# LPC43xx register map
File version: 10
CPU: CM4 r0p0, little endian, no MPU, no FPU, 3 interrupt priority bits
Registers are 32-bit, read-write, reset 0x0 unless marked. A register's access mark holds for its fields unless they carry their own. Offsets are from the block's base; [hi:lo] are bit positions; 'fields as' and 'values as' point back to an identical list.

## CCU1 — Clock Control Unit (CCU)
Base 0x40051000
0x00 PM — CCU1 power mode register
  [0] PD — Initiate power-down mode
    0=NORMAL_OPERATION_; 1=CLOCKS_WITH_WAKE_UP_ (Clocks with wake-up mode enabled (W = 1) are disabled.)
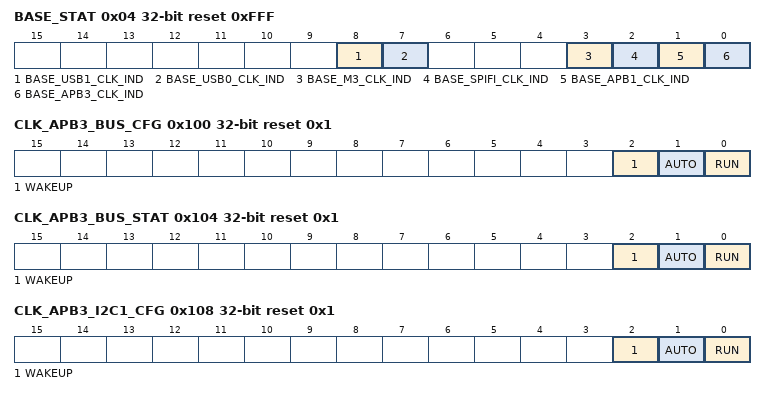
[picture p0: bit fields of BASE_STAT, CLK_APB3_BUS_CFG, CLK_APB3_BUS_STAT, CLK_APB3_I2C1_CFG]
0x04 BASE_STAT ro reset 0xFFF — CCU1 base clocks status register
  [8] BASE_USB1_CLK_IND — Base clock indicator for BASE_USB1_CLK 0 = All branch clocks switched off. 1 = at least one branch clock running.
  [7] BASE_USB0_CLK_IND — Base clock indicator for BASE_USB0_CLK 0 = All branch clocks switched off. 1 = At least one branch clock running.
  [3] BASE_M3_CLK_IND — Base clock indicator for BASE_M3_CLK 0 = All branch clocks switched off. 1 = At least one branch clock running.
  [2] BASE_SPIFI_CLK_IND — Base clock indicator for BASE_SPIFI_CLK 0 = All branch clocks switched off. 1 = At least one branch clock running.
  [1] BASE_APB1_CLK_IND — Base clock indicator for BASE_APB1_CLK 0 = All branch clocks switched off. 1 = At least one branch clock running.
  [0] BASE_APB3_CLK_IND — Base clock indicator for BASE_APB3_CLK 0 = All branch clocks switched off. 1 = At least one branch clock running.
0x100 CLK_APB3_BUS_CFG reset 0x1 — CLK_APB3_BUS clock configuration register
  [2] WAKEUP — Wake-up mechanism enable
    0=DISABLED (Wake-up is disabled.); 1=ENABLED (Wake-up is enabled.)
  [1] AUTO — Auto (AHB disable mechanism) enable
    0=DISABLED_ (Auto is disabled.); 1=ENABLED (Auto is enabled.)
  [0] RUN — Run enable
    0=DISABLED (Clock is disabled.); 1=ENABLED (Clock is enabled.)
0x104 CLK_APB3_BUS_STAT ro reset 0x1 — CLK_APB3_BUS clock status register
  [2] WAKEUP — Wake-up mechanism enable status 0 = Wake-up is disabled. 1 = Wake-up is enabled.
  [1] AUTO — Auto (AHB disable mechanism) enable status 0 = Auto is disabled. 1 = Auto is enabled.
  [0] RUN — Run enable status 0 = clock is disabled. 1 = clock is enabled.
0x108 CLK_APB3_I2C1_CFG reset 0x1 — CLK_APB3_I2C1 clock configuration register
  fields as CLK_APB3_BUS_CFG
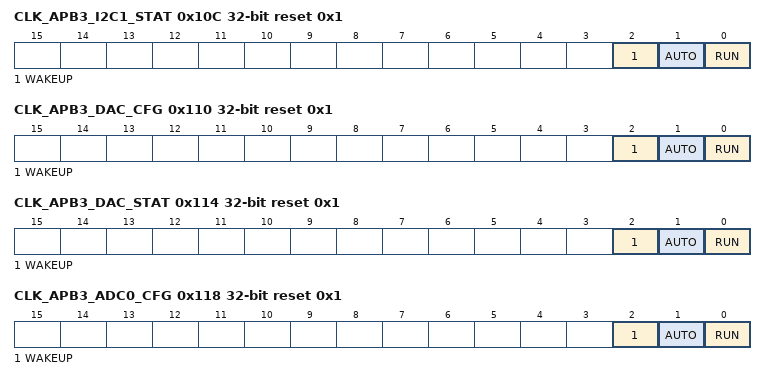
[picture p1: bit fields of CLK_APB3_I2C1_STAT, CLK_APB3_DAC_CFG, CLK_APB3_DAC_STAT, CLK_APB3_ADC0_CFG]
0x10C CLK_APB3_I2C1_STAT ro reset 0x1 — CLK_APB3_I2C1 clock status register
  fields as CLK_APB3_BUS_STAT
0x110 CLK_APB3_DAC_CFG reset 0x1 — CLK_APB3_DAC clock configuration register
  fields as CLK_APB3_BUS_CFG
0x114 CLK_APB3_DAC_STAT ro reset 0x1 — CLK_APB3_DAC clock status register
  fields as CLK_APB3_BUS_STAT
0x118 CLK_APB3_ADC0_CFG reset 0x1 — CLK_APB3_ADC0 clock configuration register
  fields as CLK_APB3_BUS_CFG
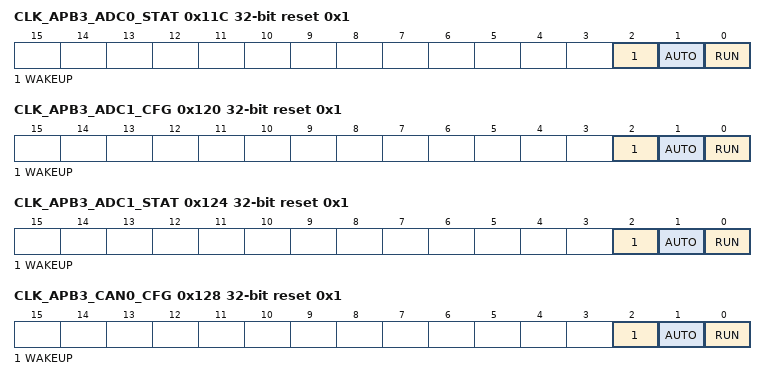
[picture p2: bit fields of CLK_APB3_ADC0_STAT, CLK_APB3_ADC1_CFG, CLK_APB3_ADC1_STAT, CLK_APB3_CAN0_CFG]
0x11C CLK_APB3_ADC0_STAT ro reset 0x1 — CLK_APB3_ADC0 clock status register
  fields as CLK_APB3_BUS_STAT
0x120 CLK_APB3_ADC1_CFG reset 0x1 — CLK_APB3_ADC1 clock configuration register
  fields as CLK_APB3_BUS_CFG
0x124 CLK_APB3_ADC1_STAT ro reset 0x1 — CLK_APB3_ADC1 clock status register
  fields as CLK_APB3_BUS_STAT
0x128 CLK_APB3_CAN0_CFG reset 0x1 — CLK_APB3_CAN0 clock configuration register
  fields as CLK_APB3_BUS_CFG
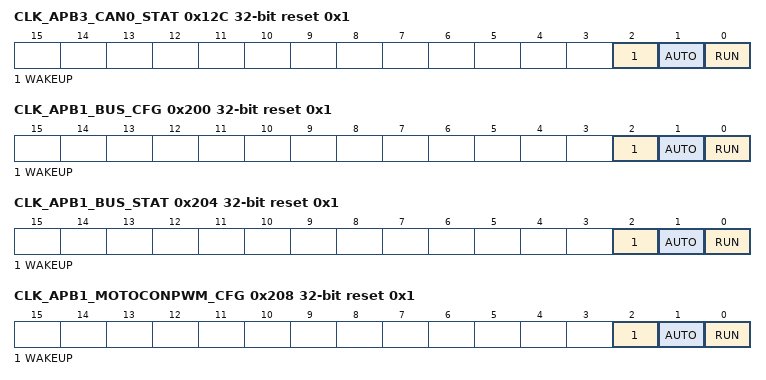
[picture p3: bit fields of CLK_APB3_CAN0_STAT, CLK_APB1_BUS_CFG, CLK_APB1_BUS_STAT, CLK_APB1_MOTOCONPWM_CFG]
0x12C CLK_APB3_CAN0_STAT ro reset 0x1 — CLK_APB3_CAN0 clock status register
  fields as CLK_APB3_BUS_STAT
0x200 CLK_APB1_BUS_CFG reset 0x1 — CLK_APB1_BUS clock configuration register
  fields as CLK_APB3_BUS_CFG
0x204 CLK_APB1_BUS_STAT ro reset 0x1 — CLK_APB1_BUS clock status register
  fields as CLK_APB3_BUS_STAT
0x208 CLK_APB1_MOTOCONPWM_CFG reset 0x1 — CLK_APB1_MOTOCONPWM clock configuration register
  fields as CLK_APB3_BUS_CFG
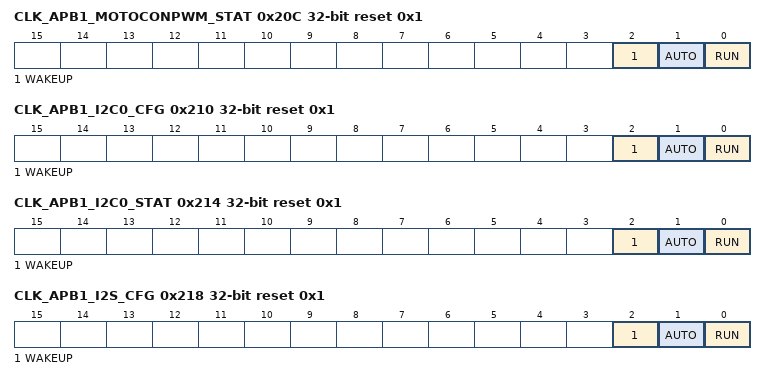
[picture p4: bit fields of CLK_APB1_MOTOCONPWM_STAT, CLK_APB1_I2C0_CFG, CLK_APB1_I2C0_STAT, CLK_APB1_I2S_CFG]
0x20C CLK_APB1_MOTOCONPWM_STAT ro reset 0x1 — CLK_APB1_MOTOCONPWM clock status register
  fields as CLK_APB3_BUS_STAT
0x210 CLK_APB1_I2C0_CFG reset 0x1 — CLK_ABP1_I2C0 clock configuration register
  fields as CLK_APB3_BUS_CFG
0x214 CLK_APB1_I2C0_STAT ro reset 0x1 — CLK_APB1_I2C0 clock status register
  fields as CLK_APB3_BUS_STAT
0x218 CLK_APB1_I2S_CFG reset 0x1 — CLK_APB1_I2S clock configuration register
  fields as CLK_APB3_BUS_CFG
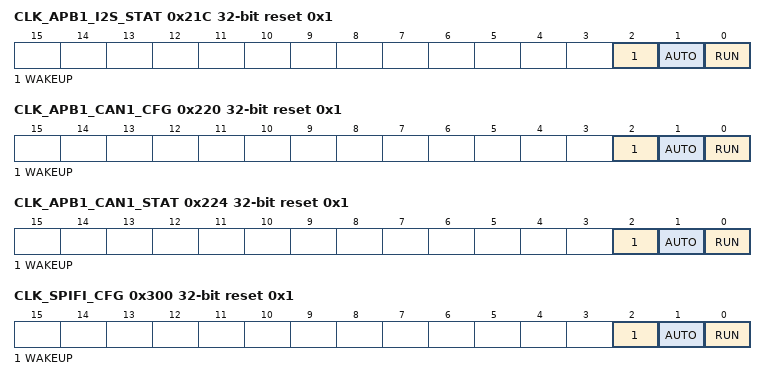
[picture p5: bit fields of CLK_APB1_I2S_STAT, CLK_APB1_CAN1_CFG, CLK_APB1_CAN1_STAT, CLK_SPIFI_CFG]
0x21C CLK_APB1_I2S_STAT ro reset 0x1 — CLK_APB1_I2S clock status register
  fields as CLK_APB3_BUS_STAT
0x220 CLK_APB1_CAN1_CFG reset 0x1 — CLK_APB1_CAN1 clock configuration register
  fields as CLK_APB3_BUS_CFG
0x224 CLK_APB1_CAN1_STAT ro reset 0x1 — CLK_APB1_CAN1 clock status register
  fields as CLK_APB3_BUS_STAT
0x300 CLK_SPIFI_CFG reset 0x1 — CLK_SPIFI clock configuration register
  fields as CLK_APB3_BUS_CFG
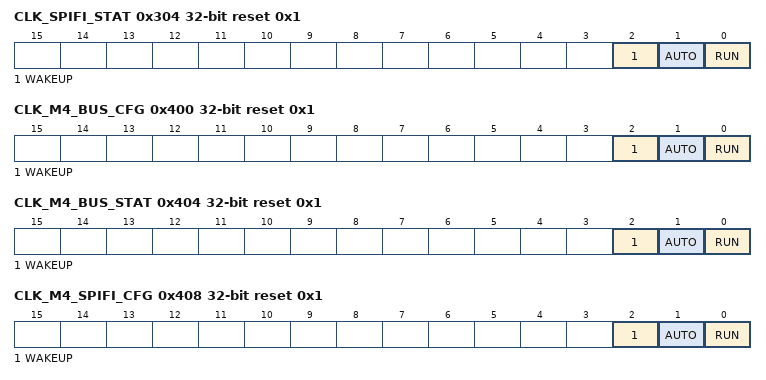
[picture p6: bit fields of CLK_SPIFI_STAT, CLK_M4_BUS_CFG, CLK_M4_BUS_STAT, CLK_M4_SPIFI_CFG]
0x304 CLK_SPIFI_STAT ro reset 0x1 — CLK_APB1_SPIFI clock status register
  fields as CLK_APB3_BUS_STAT
0x400 CLK_M4_BUS_CFG reset 0x1 — CLK_M4_BUS clock configuration register
  fields as CLK_APB3_BUS_CFG
0x404 CLK_M4_BUS_STAT ro reset 0x1 — CLK_M4_BUSclock status register
  fields as CLK_APB3_BUS_STAT
0x408 CLK_M4_SPIFI_CFG reset 0x1 — CLK_M4_SPIFI clock configuration register
  fields as CLK_APB3_BUS_CFG
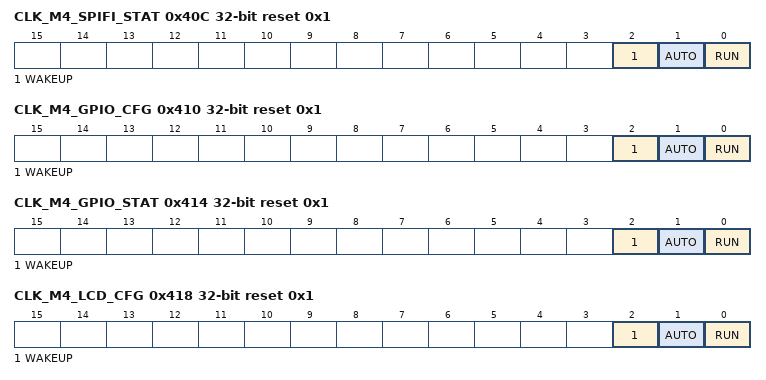
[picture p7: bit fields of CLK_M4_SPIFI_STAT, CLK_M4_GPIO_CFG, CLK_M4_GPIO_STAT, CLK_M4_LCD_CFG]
0x40C CLK_M4_SPIFI_STAT ro reset 0x1 — CLK_M4_SPIFI clock status register
  fields as CLK_APB3_BUS_STAT
0x410 CLK_M4_GPIO_CFG reset 0x1 — CLK_M4_GPIO clock configuration register
  fields as CLK_APB3_BUS_CFG
0x414 CLK_M4_GPIO_STAT ro reset 0x1 — CLK_M4_GPIO clock status register
  fields as CLK_APB3_BUS_STAT
0x418 CLK_M4_LCD_CFG reset 0x1 — CLK_M4_LCD clock configuration register
  fields as CLK_APB3_BUS_CFG
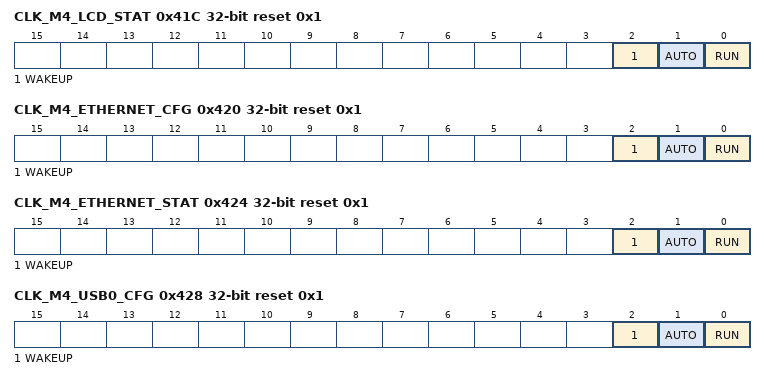
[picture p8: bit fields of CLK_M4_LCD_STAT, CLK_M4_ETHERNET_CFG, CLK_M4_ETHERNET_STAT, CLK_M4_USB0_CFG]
0x41C CLK_M4_LCD_STAT ro reset 0x1 — CLK_M4_LCD clock status register
  fields as CLK_APB3_BUS_STAT
0x420 CLK_M4_ETHERNET_CFG reset 0x1 — CLK_M4_ETHERNET clock configuration register
  fields as CLK_APB3_BUS_CFG
0x424 CLK_M4_ETHERNET_STAT ro reset 0x1 — CLK_M4_ETHERNET clock status register
  fields as CLK_APB3_BUS_STAT
0x428 CLK_M4_USB0_CFG reset 0x1 — CLK_M4_USB0 clock configuration register
  fields as CLK_APB3_BUS_CFG
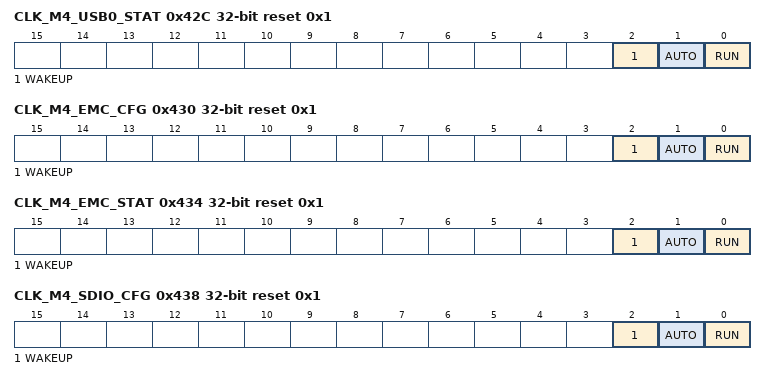
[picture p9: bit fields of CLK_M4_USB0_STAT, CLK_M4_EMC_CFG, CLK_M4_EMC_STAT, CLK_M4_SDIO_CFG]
0x42C CLK_M4_USB0_STAT ro reset 0x1 — CLK_M4_USB0 clock status register
  fields as CLK_APB3_BUS_STAT
0x430 CLK_M4_EMC_CFG reset 0x1 — CLK_M4_EMC clock configuration register
  fields as CLK_APB3_BUS_CFG
0x434 CLK_M4_EMC_STAT ro reset 0x1 — CLK_M4_EMC clock status register
  fields as CLK_APB3_BUS_STAT
0x438 CLK_M4_SDIO_CFG reset 0x1 — CLK_M4_SDIO clock configuration register
  fields as CLK_APB3_BUS_CFG
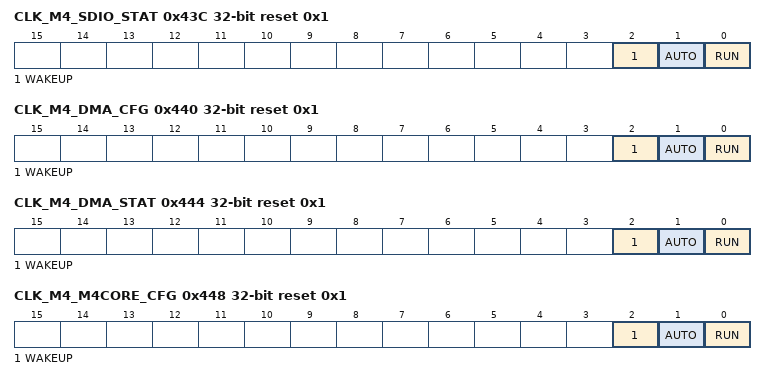
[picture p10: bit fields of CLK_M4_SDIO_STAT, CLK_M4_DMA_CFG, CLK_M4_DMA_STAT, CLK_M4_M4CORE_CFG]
0x43C CLK_M4_SDIO_STAT ro reset 0x1 — CLK_M4_SDIO clock status register
  fields as CLK_APB3_BUS_STAT
0x440 CLK_M4_DMA_CFG reset 0x1 — CLK_M4_DMA clock configuration register
  fields as CLK_APB3_BUS_CFG
0x444 CLK_M4_DMA_STAT ro reset 0x1 — CLK_M4_DMA clock status register
  fields as CLK_APB3_BUS_STAT
0x448 CLK_M4_M4CORE_CFG reset 0x1 — CLK_M4_M4CORE clock configuration register
  fields as CLK_APB3_BUS_CFG
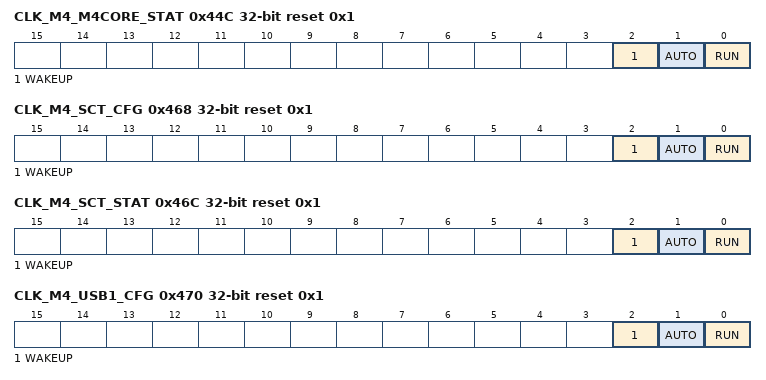
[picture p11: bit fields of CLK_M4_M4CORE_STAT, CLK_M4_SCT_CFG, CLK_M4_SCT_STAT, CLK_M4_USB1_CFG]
0x44C CLK_M4_M4CORE_STAT ro reset 0x1 — CLK_M4_M3CORE clock status register
  fields as CLK_APB3_BUS_STAT
0x468 CLK_M4_SCT_CFG reset 0x1 — CLK_M4_SCT clock configuration register
  fields as CLK_APB3_BUS_CFG
0x46C CLK_M4_SCT_STAT ro reset 0x1 — CLK_M4_SCT clock status register
  fields as CLK_APB3_BUS_STAT
0x470 CLK_M4_USB1_CFG reset 0x1 — CLK_M4_USB1 clock configuration register
  fields as CLK_APB3_BUS_CFG
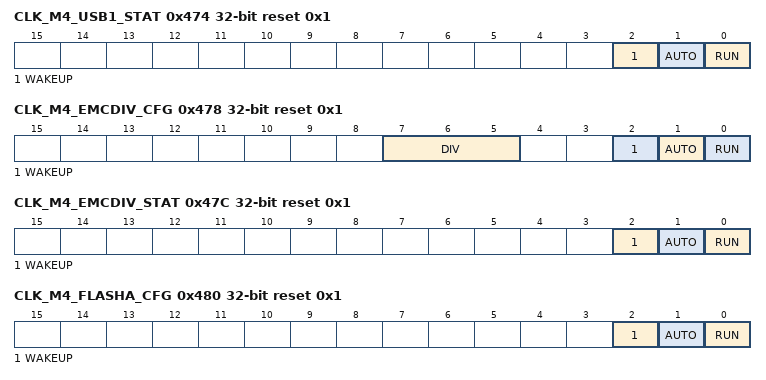
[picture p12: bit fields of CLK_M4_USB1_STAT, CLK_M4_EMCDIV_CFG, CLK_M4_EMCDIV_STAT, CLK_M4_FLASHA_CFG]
0x474 CLK_M4_USB1_STAT ro reset 0x1 — CLK_M4_USB1 clock status register
  fields as CLK_APB3_BUS_STAT
0x478 CLK_M4_EMCDIV_CFG reset 0x1 — CLK_M4_EMCDIV clock configuration register
  [7:5] DIV — Clock divider value
    0=DIVIDEBY1 (No division. Divide by 1.); 1=DIVIDEBY2
  [2] WAKEUP — Wake-up mechanism enable
    values as CLK_APB3_BUS_CFG.WAKEUP
  [1] AUTO — Auto (AHB disable mechanism) enable
    values as CLK_APB3_BUS_CFG.AUTO
  [0] RUN — Run enable
    values as CLK_APB3_BUS_CFG.RUN
0x47C CLK_M4_EMCDIV_STAT ro reset 0x1 — CLK_M4_EMCDIV clock status register
  fields as CLK_APB3_BUS_STAT
0x480 CLK_M4_FLASHA_CFG reset 0x1 — CLK_M4_FLASHA clock configuration register
  fields as CLK_APB3_BUS_CFG
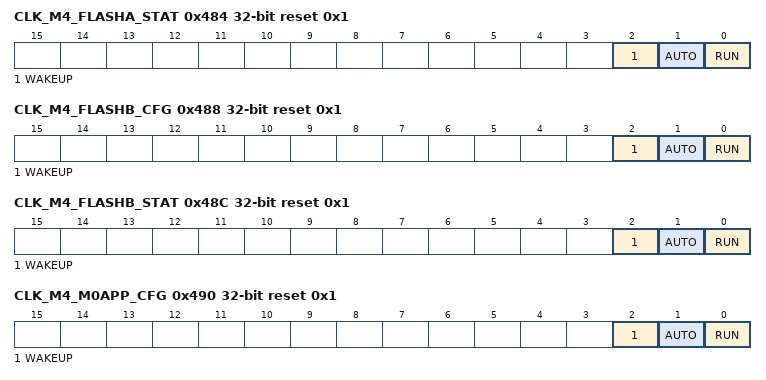
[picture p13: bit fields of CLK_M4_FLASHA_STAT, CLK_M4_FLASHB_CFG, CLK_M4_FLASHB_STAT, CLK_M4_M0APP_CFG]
0x484 CLK_M4_FLASHA_STAT ro reset 0x1 — CLK_M4_FLASHA clock status register
  fields as CLK_APB3_BUS_STAT
0x488 CLK_M4_FLASHB_CFG reset 0x1 — CLK_M4_FLASHB clock configuration register
  fields as CLK_APB3_BUS_CFG
0x48C CLK_M4_FLASHB_STAT ro reset 0x1 — CLK_M4_FLASHB clock status register
  fields as CLK_APB3_BUS_STAT
0x490 CLK_M4_M0APP_CFG reset 0x1 — CLK_M0APP_CFG clock configuration register
  fields as CLK_APB3_BUS_CFG
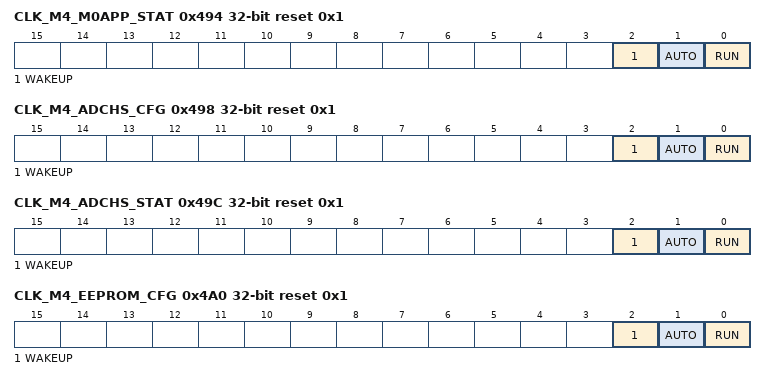
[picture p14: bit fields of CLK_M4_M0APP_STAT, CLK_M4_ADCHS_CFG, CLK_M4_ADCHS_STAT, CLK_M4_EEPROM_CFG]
0x494 CLK_M4_M0APP_STAT ro reset 0x1 — CLK_M4_MOAPP clock status register
  fields as CLK_APB3_BUS_STAT
0x498 CLK_M4_ADCHS_CFG reset 0x1 — CLK_ADCHS_CFG clock configuration register
  fields as CLK_APB3_BUS_CFG
0x49C CLK_M4_ADCHS_STAT ro reset 0x1 — CLK_M4_ADCHS clock status register
  fields as CLK_APB3_BUS_STAT
0x4A0 CLK_M4_EEPROM_CFG reset 0x1 — CLK_EEPROM_CFG clock configuration register
  fields as CLK_APB3_BUS_CFG
0x4A4 CLK_M4_EEPROM_STAT ro reset 0x1 — CLK_M4_EEPROM clock status register
  fields as CLK_APB3_BUS_STAT
0x500 CLK_M4_WWDT_CFG reset 0x1 — CLK_M4_WWDT clock configuration register
  fields as CLK_APB3_BUS_CFG
0x504 CLK_M4_WWDT_STAT ro reset 0x1 — CLK_M4_WWDT clock status register
  fields as CLK_APB3_BUS_STAT
0x508 CLK_M4_USART0_CFG reset 0x1 — CLK_M4_USART0 clock configuration register
  fields as CLK_APB3_BUS_CFG
0x50C CLK_M4_USART0_STAT ro reset 0x1 — CLK_M4_USART0 clock status register
  fields as CLK_APB3_BUS_STAT
0x510 CLK_M4_UART1_CFG reset 0x1 — CLK_M4_UART1 clock configuration register
  fields as CLK_APB3_BUS_CFG
0x514 CLK_M4_UART1_STAT ro reset 0x1 — CLK_M4_UART1 clock status register
  fields as CLK_APB3_BUS_STAT
0x518 CLK_M4_SSP0_CFG reset 0x1 — CLK_M4_SSP0 clock configuration register
  fields as CLK_APB3_BUS_CFG
0x51C CLK_M4_SSP0_STAT ro reset 0x1 — CLK_M4_SSP0 clock status register
  fields as CLK_APB3_BUS_STAT
0x520 CLK_M4_TIMER0_CFG reset 0x1 — CLK_M4_TIMER0 clock configuration register
  fields as CLK_APB3_BUS_CFG
0x524 CLK_M4_TIMER0_STAT ro reset 0x1 — CLK_M4_TIMER0 clock status register
  fields as CLK_APB3_BUS_STAT
0x528 CLK_M4_TIMER1_CFG reset 0x1 — CLK_M4_TIMER1clock configuration register
  fields as CLK_APB3_BUS_CFG
0x52C CLK_M4_TIMER1_STAT ro reset 0x1 — CLK_M4_TIMER1 clock status register
  fields as CLK_APB3_BUS_STAT
0x530 CLK_M4_SCU_CFG reset 0x1 — CLK_M4_SCU clock configuration register
  fields as CLK_APB3_BUS_CFG
0x534 CLK_M4_SCU_STAT ro reset 0x1 — CLK_SCU_XXX clock status register
  fields as CLK_APB3_BUS_STAT
0x538 CLK_M4_CREG_CFG reset 0x1 — CLK_M4_CREGclock configuration register
  fields as CLK_APB3_BUS_CFG
0x53C CLK_M4_CREG_STAT ro reset 0x1 — CLK_M4_CREG clock status register
  fields as CLK_APB3_BUS_STAT
0x600 CLK_M4_RITIMER_CFG reset 0x1 — CLK_M4_RITIMER clock configuration register
  fields as CLK_APB3_BUS_CFG
0x604 CLK_M4_RITIMER_STAT ro reset 0x1 — CLK_M4_RITIMER clock status register
  fields as CLK_APB3_BUS_STAT
0x608 CLK_M4_USART2_CFG reset 0x1 — CLK_M4_USART2 clock configuration register
  fields as CLK_APB3_BUS_CFG
0x60C CLK_M4_USART2_STAT ro reset 0x1 — CLK_M4_USART2 clock status register
  fields as CLK_APB3_BUS_STAT
0x610 CLK_M4_USART3_CFG reset 0x1 — CLK_M4_USART3 clock configuration register
  fields as CLK_APB3_BUS_CFG
0x614 CLK_M4_USART3_STAT ro reset 0x1 — CLK_M4_USART3 clock status register
  fields as CLK_APB3_BUS_STAT
0x618 CLK_M4_TIMER2_CFG reset 0x1 — CLK_M4_TIMER2 clock configuration register
  fields as CLK_APB3_BUS_CFG
0x61C CLK_M4_TIMER2_STAT ro reset 0x1 — CLK_M4_TIMER2 clock status register
  fields as CLK_APB3_BUS_STAT
0x620 CLK_M4_TIMER3_CFG reset 0x1 — CLK_M4_TIMER3 clock configuration register
  fields as CLK_APB3_BUS_CFG
0x624 CLK_M4_TIMER3_STAT ro reset 0x1 — CLK_M4_TIMER3 clock status register
  fields as CLK_APB3_BUS_STAT
0x628 CLK_M4_SSP1_CFG reset 0x1 — CLK_M4_SSP1 clock configuration register
  fields as CLK_APB3_BUS_CFG
0x62C CLK_M4_SSP1_STAT ro reset 0x1 — CLK_M4_SSP1 clock status register
  fields as CLK_APB3_BUS_STAT
0x630 CLK_M4_QEI_CFG reset 0x1 — CLK_M4_QEIclock configuration register
  fields as CLK_APB3_BUS_CFG
0x634 CLK_M4_QEI_STAT ro reset 0x1 — CLK_M4_QEI clock status register
  fields as CLK_APB3_BUS_STAT
0x700 CLK_PERIPH_BUS_CFG reset 0x1 — CLK_PERIPH_BUS_CFG clock configuration register
  fields as CLK_APB3_BUS_CFG
0x704 CLK_PERIPH_BUS_STAT ro reset 0x1 — CLK_PERIPH_BUS_STAT clock status register
  fields as CLK_APB3_BUS_STAT
0x710 CLK_PERIPH_CORE_CFG reset 0x1 — CLK_PERIPH_CORE_CFG clock configuration register
  fields as CLK_APB3_BUS_CFG
0x714 CLK_PERIPH_CORE_STAT ro reset 0x1 — CLK_CORE_BUS_STAT clock status register
  fields as CLK_APB3_BUS_STAT
0x718 CLK_PERIPH_SGPIO_CFG reset 0x1 — CLK_PERIPH_SGPIO_CFG clock configuration register
  fields as CLK_APB3_BUS_CFG
0x71C CLK_PERIPH_SGPIO_STAT ro reset 0x1 — CLK_CORE_SGPIO_STAT clock status register
  fields as CLK_APB3_BUS_STAT
0x800 CLK_USB0_CFG reset 0x1 — CLK_M4_USB0 clock configuration register
  [2] WAKEUP — Wake-up mechanism enable
    0=WAKE_UP_IS_DISABLED_; 1=WAKE_UP_IS_ENABLED_
  [1] AUTO — Auto (AHB disable mechanism) enable
    0=AUTO_IS_DISABLED_; 1=AUTO_IS_ENABLED_
  [0] RUN — Run enable
    values as CLK_APB3_BUS_CFG.RUN
0x804 CLK_USB0_STAT ro reset 0x1 — CLK_USB0 clock status register
  fields as CLK_APB3_BUS_STAT
0x900 CLK_USB1_CFG reset 0x1 — CLK_USB1 clock configuration register
  fields as CLK_USB0_CFG
0x904 CLK_USB1_STAT ro reset 0x1 — CLK_USB1 clock status register
  fields as CLK_APB3_BUS_STAT
0xA00 CLK_SPI_CFG reset 0x1 — CLK_SPI clock configuration register
  fields as CLK_USB0_CFG
0xA04 CLK_SPI_STAT ro reset 0x1 — CLK_SPI clock status register
  fields as CLK_APB3_BUS_STAT
0xB00 CLK_ADCHS_CFG reset 0x1 — CLK_ADCHS clock configuration register
  fields as CLK_USB0_CFG
0xB04 CLK_ADCHS_STAT ro reset 0x1 — CLK_ADCHS clock status register
  fields as CLK_APB3_BUS_STAT
